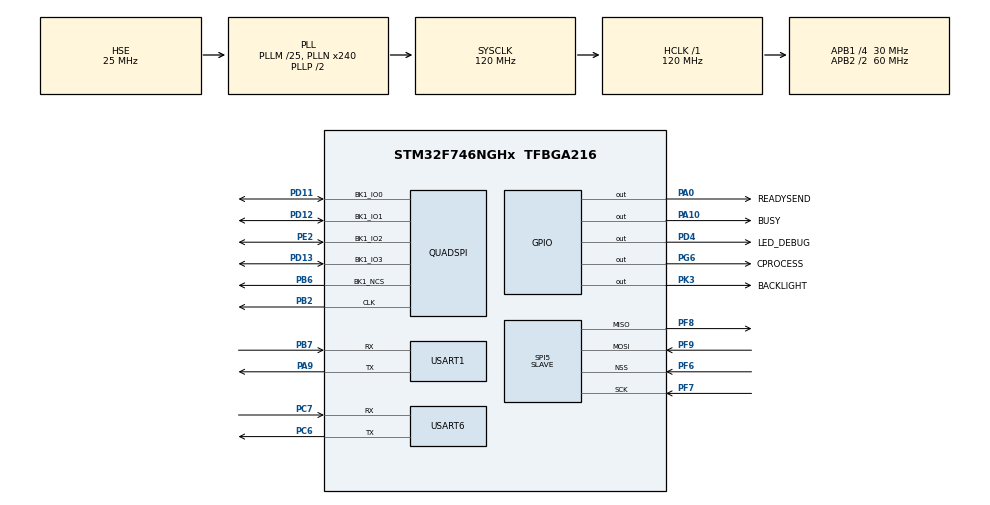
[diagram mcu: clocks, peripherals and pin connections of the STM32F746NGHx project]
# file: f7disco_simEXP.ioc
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CORTEX_M7.CPU_DCache=Disabled
CORTEX_M7.CPU_ICache=Disabled
CORTEX_M7.default_mode_Activation=0
Dma.Request0=SPI5_TX
Dma.SPI5_TX.0.Direction=DMA_MEMORY_TO_PERIPH
Dma.SPI5_TX.0.FIFOMode=DMA_FIFOMODE_DISABLE
Dma.SPI5_TX.0.Instance=DMA2_Stream4
Dma.SPI5_TX.0.MemDataAlignment=DMA_MDATAALIGN_BYTE
Dma.SPI5_TX.0.MemInc=DMA_MINC_ENABLE
Dma.SPI5_TX.0.Mode=DMA_NORMAL
Dma.SPI5_TX.0.PeriphDataAlignment=DMA_PDATAALIGN_BYTE
Dma.SPI5_TX.0.PeriphInc=DMA_PINC_DISABLE
Dma.SPI5_TX.0.Priority=DMA_PRIORITY_LOW
Mcu.Family=STM32F7
Mcu.Name=STM32F746NGHx
Mcu.Package=TFBGA216
NVIC.DMA2_Stream4_IRQn=true\:0\:0\:false\:false\:true\:false\:true\:true
NVIC.PriorityGroup=NVIC_PRIORITYGROUP_4
NVIC.SPI5_IRQn=true\:0\:0\:false\:false\:true\:true\:true\:true
NVIC.USART1_IRQn=true\:0\:0\:false\:false\:true\:true\:true\:true
NVIC.USART6_IRQn=true\:0\:0\:false\:false\:true\:true\:true\:true
PA0/WKUP.GPIO_Label=READYSEND
PA0/WKUP.PinState=GPIO_PIN_SET
PA0/WKUP.Signal=GPIO_Output
PA10.GPIO_Label=BUSY
PA10.PinState=GPIO_PIN_SET
PA10.Signal=GPIO_Output
PA9.Mode=Asynchronous
PA9.Signal=USART1_TX
PB2.Mode=Single Bank 1
PB2.Signal=QUADSPI_CLK
PB6.Mode=Single Bank 1
PB6.Signal=QUADSPI_BK1_NCS
PB7.Mode=Asynchronous
PB7.Signal=USART1_RX
PC6.Mode=Asynchronous
PC6.Signal=USART6_TX
PC7.Mode=Asynchronous
PC7.Signal=USART6_RX
PD11.Mode=Single Bank 1
PD11.Signal=QUADSPI_BK1_IO0
PD12.Mode=Single Bank 1
PD12.Signal=QUADSPI_BK1_IO1
PD13.Mode=Single Bank 1
PD13.Signal=QUADSPI_BK1_IO3
PD4.GPIO_Label=LED_DEBUG
PD4.Signal=GPIO_Output
PE2.Mode=Single Bank 1
PE2.Signal=QUADSPI_BK1_IO2
PF6.Mode=NSS_Signal_Hard_Input
PF6.Signal=SPI5_NSS
PF7.Mode=Full_Duplex_Slave
PF7.Signal=SPI5_SCK
PF8.Mode=Full_Duplex_Slave
PF8.Signal=SPI5_MISO
PF9.Mode=Full_Duplex_Slave
PF9.Signal=SPI5_MOSI
PG6.GPIO_Label=CPROCESS
PG6.PinState=GPIO_PIN_SET
PG6.Signal=GPIO_Output
PH0/OSC_IN.Mode=HSE-External-Clock-Source
PH0/OSC_IN.Signal=RCC_OSC_IN
PH1/OSC_OUT.Mode=HSE-External-Clock-Source
PH1/OSC_OUT.Signal=RCC_OSC_OUT
PK3.GPIO_Label=BACKLIGHT
PK3.Signal=GPIO_Output
ProjectManager.HeapSize=0x400
ProjectManager.StackSize=0x800
ProjectManager.TargetToolchain=STM32CubeIDE
QUADSPI.ChipSelectHighTime=QSPI_CS_HIGH_TIME_6_CYCLE
QUADSPI.ClockPrescaler=23
QUADSPI.FifoThreshold=4
QUADSPI.FlashSize=23
QUADSPI.SampleShifting=QSPI_SAMPLE_SHIFTING_HALFCYCLE
RCC.AHBFreq_Value=120000000
RCC.APB1CLKDivider=RCC_HCLK_DIV4
RCC.APB1Freq_Value=30000000
RCC.APB1TimFreq_Value=60000000
RCC.APB2CLKDivider=RCC_HCLK_DIV2
RCC.APB2Freq_Value=60000000
RCC.APB2TimFreq_Value=120000000
RCC.CortexFreq_Value=120000000
RCC.HCLKFreq_Value=120000000
RCC.HSE_VALUE=25000000
RCC.HSI_VALUE=16000000
RCC.LSE_VALUE=32768
RCC.PLLM=25
RCC.PLLN=240
RCC.PLLSourceVirtual=RCC_PLLSOURCE_HSE
RCC.SYSCLKFreq_VALUE=120000000
RCC.SYSCLKSource=RCC_SYSCLKSOURCE_PLLCLK
RCC.USBFreq_Value=120000000
RCC.VCOOutputFreq_Value=240000000
SPI5.DataSize=SPI_DATASIZE_8BIT
SPI5.Direction=SPI_DIRECTION_2LINES
SPI5.Mode=SPI_MODE_SLAVE
SPI5.VirtualNSS=VM_NSSHARD
SPI5.VirtualType=VM_SLAVE
USART1.VirtualMode-Asynchronous=VM_ASYNC
USART6.VirtualMode-Asynchronous=VM_ASYNC
board=custom

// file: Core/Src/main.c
/* USER CODE BEGIN Header */
/**
  ******************************************************************************
  * @file           : main.c
  * @brief          : Main program body
  ******************************************************************************
  * @attention
  *
  * Copyright (c) 2025 STMicroelectronics.
  * All rights reserved.
  *
  * This software is licensed under terms that can be found in the LICENSE file
  * in the root directory of this software component.
  * If no LICENSE file comes with this software, it is provided AS-IS.
  *
  ******************************************************************************
  */
/* USER CODE END Header */
#include "main.h"

/* USER CODE BEGIN Includes */
#include "stdio.h"
#include "Mgmt/mgmt.h"
#include "Logger/log.h"
/* USER CODE END Includes */

QSPI_HandleTypeDef hqspi;

UART_HandleTypeDef huart1;

void SystemClock_Config(void);
static void MX_GPIO_Init(void);
static void MX_DMA_Init(void);
static void MX_USART1_UART_Init(void);
static void MX_QUADSPI_Init(void);
static void MX_USART6_UART_Init(void);
static void MX_SPI5_Init(void);

/* USER CODE BEGIN 0 */
#define PRINTF2USART1 int __io_putchar(int data)
/* USER CODE END 0 */

int main(void)
{

  /* MCU Configuration--------------------------------------------------------*/

  /* Reset of all peripherals, Initializes the Flash interface and the Systick. */
  HAL_Init();

  /* Configure the system clock */
  SystemClock_Config();

  /* Initialize all configured peripherals */
  MX_GPIO_Init();
  MX_DMA_Init();
  MX_USART1_UART_Init();
  MX_QUADSPI_Init();
  MX_USART6_UART_Init();
  MX_SPI5_Init();
  /* USER CODE BEGIN 2 */
  Mgmt_SystemInitStepZero();

  Mgmt_SystemInitFinal();

  Mgmt_SystemStart();
  /* USER CODE END 2 */

  /* Infinite loop */
  while (1)
  {

  }
}

void SystemClock_Config(void)
{
  RCC_OscInitTypeDef RCC_OscInitStruct = {0};
  RCC_ClkInitTypeDef RCC_ClkInitStruct = {0};

  /** Configure the main internal regulator output voltage
  */
  __HAL_RCC_PWR_CLK_ENABLE();
  __HAL_PWR_VOLTAGESCALING_CONFIG(PWR_REGULATOR_VOLTAGE_SCALE3);

  /** Initializes the RCC Oscillators according to the specified parameters
  * in the RCC_OscInitTypeDef structure.
  */
  RCC_OscInitStruct.OscillatorType = RCC_OSCILLATORTYPE_HSE;
  RCC_OscInitStruct.HSEState = RCC_HSE_BYPASS;
  RCC_OscInitStruct.PLL.PLLState = RCC_PLL_ON;
  RCC_OscInitStruct.PLL.PLLSource = RCC_PLLSOURCE_HSE;
  RCC_OscInitStruct.PLL.PLLM = 25;
  RCC_OscInitStruct.PLL.PLLN = 240;
  RCC_OscInitStruct.PLL.PLLP = RCC_PLLP_DIV2;
  RCC_OscInitStruct.PLL.PLLQ = 2;
  if (HAL_RCC_OscConfig(&RCC_OscInitStruct) != HAL_OK)
  {
    Error_Handler();
  }

  /** Initializes the CPU, AHB and APB buses clocks
  */
  RCC_ClkInitStruct.ClockType = RCC_CLOCKTYPE_HCLK|RCC_CLOCKTYPE_SYSCLK
                              |RCC_CLOCKTYPE_PCLK1|RCC_CLOCKTYPE_PCLK2;
  RCC_ClkInitStruct.SYSCLKSource = RCC_SYSCLKSOURCE_PLLCLK;
  RCC_ClkInitStruct.AHBCLKDivider = RCC_SYSCLK_DIV1;
  RCC_ClkInitStruct.APB1CLKDivider = RCC_HCLK_DIV4;
  RCC_ClkInitStruct.APB2CLKDivider = RCC_HCLK_DIV2;

  if (HAL_RCC_ClockConfig(&RCC_ClkInitStruct, FLASH_LATENCY_3) != HAL_OK)
  {
    Error_Handler();
  }
}

static void MX_QUADSPI_Init(void)
{

  /* QUADSPI parameter configuration*/
  hqspi.Instance = QUADSPI;
  hqspi.Init.ClockPrescaler = 23;
  hqspi.Init.FifoThreshold = 4;
  hqspi.Init.SampleShifting = QSPI_SAMPLE_SHIFTING_HALFCYCLE;
  hqspi.Init.FlashSize = 23;
  hqspi.Init.ChipSelectHighTime = QSPI_CS_HIGH_TIME_6_CYCLE;
  hqspi.Init.ClockMode = QSPI_CLOCK_MODE_0;
  hqspi.Init.FlashID = QSPI_FLASH_ID_1;
  hqspi.Init.DualFlash = QSPI_DUALFLASH_DISABLE;
  if (HAL_QSPI_Init(&hqspi) != HAL_OK)
  {
    Error_Handler();
  }

}

static void MX_SPI5_Init(void)
{

  LL_SPI_InitTypeDef SPI_InitStruct = {0};

  LL_GPIO_InitTypeDef GPIO_InitStruct = {0};

  /* Peripheral clock enable */
  LL_APB2_GRP1_EnableClock(LL_APB2_GRP1_PERIPH_SPI5);

  LL_AHB1_GRP1_EnableClock(LL_AHB1_GRP1_PERIPH_GPIOF);
  /**SPI5 GPIO Configuration
  PF7   ------> SPI5_SCK
  PF6   ------> SPI5_NSS
  PF9   ------> SPI5_MOSI
  PF8   ------> SPI5_MISO
  */
  GPIO_InitStruct.Pin = LL_GPIO_PIN_7;
  GPIO_InitStruct.Mode = LL_GPIO_MODE_ALTERNATE;
  GPIO_InitStruct.Speed = LL_GPIO_SPEED_FREQ_VERY_HIGH;
  GPIO_InitStruct.OutputType = LL_GPIO_OUTPUT_PUSHPULL;
  GPIO_InitStruct.Pull = LL_GPIO_PULL_NO;
  GPIO_InitStruct.Alternate = LL_GPIO_AF_5;
  LL_GPIO_Init(GPIOF, &GPIO_InitStruct);

  GPIO_InitStruct.Pin = LL_GPIO_PIN_6;
  GPIO_InitStruct.Mode = LL_GPIO_MODE_ALTERNATE;
  GPIO_InitStruct.Speed = LL_GPIO_SPEED_FREQ_VERY_HIGH;
  GPIO_InitStruct.OutputType = LL_GPIO_OUTPUT_PUSHPULL;
  GPIO_InitStruct.Pull = LL_GPIO_PULL_NO;
  GPIO_InitStruct.Alternate = LL_GPIO_AF_5;
  LL_GPIO_Init(GPIOF, &GPIO_InitStruct);

  GPIO_InitStruct.Pin = LL_GPIO_PIN_9;
  GPIO_InitStruct.Mode = LL_GPIO_MODE_ALTERNATE;
  GPIO_InitStruct.Speed = LL_GPIO_SPEED_FREQ_VERY_HIGH;
  GPIO_InitStruct.OutputType = LL_GPIO_OUTPUT_PUSHPULL;
  GPIO_InitStruct.Pull = LL_GPIO_PULL_NO;
  GPIO_InitStruct.Alternate = LL_GPIO_AF_5;
  LL_GPIO_Init(GPIOF, &GPIO_InitStruct);

  GPIO_InitStruct.Pin = LL_GPIO_PIN_8;
  GPIO_InitStruct.Mode = LL_GPIO_MODE_ALTERNATE;
  GPIO_InitStruct.Speed = LL_GPIO_SPEED_FREQ_VERY_HIGH;
  GPIO_InitStruct.OutputType = LL_GPIO_OUTPUT_PUSHPULL;
  GPIO_InitStruct.Pull = LL_GPIO_PULL_NO;
  GPIO_InitStruct.Alternate = LL_GPIO_AF_5;
  LL_GPIO_Init(GPIOF, &GPIO_InitStruct);

  /* SPI5 DMA Init */

  /* SPI5_TX Init */
  LL_DMA_SetChannelSelection(DMA2, LL_DMA_STREAM_4, LL_DMA_CHANNEL_2);

  LL_DMA_SetDataTransferDirection(DMA2, LL_DMA_STREAM_4, LL_DMA_DIRECTION_MEMORY_TO_PERIPH);

  LL_DMA_SetStreamPriorityLevel(DMA2, LL_DMA_STREAM_4, LL_DMA_PRIORITY_LOW);

  LL_DMA_SetMode(DMA2, LL_DMA_STREAM_4, LL_DMA_MODE_NORMAL);

  LL_DMA_SetPeriphIncMode(DMA2, LL_DMA_STREAM_4, LL_DMA_PERIPH_NOINCREMENT);

  LL_DMA_SetMemoryIncMode(DMA2, LL_DMA_STREAM_4, LL_DMA_MEMORY_INCREMENT);

  LL_DMA_SetPeriphSize(DMA2, LL_DMA_STREAM_4, LL_DMA_PDATAALIGN_BYTE);

  LL_DMA_SetMemorySize(DMA2, LL_DMA_STREAM_4, LL_DMA_MDATAALIGN_BYTE);

  LL_DMA_DisableFifoMode(DMA2, LL_DMA_STREAM_4);

  /* SPI5 interrupt Init */
  NVIC_SetPriority(SPI5_IRQn, NVIC_EncodePriority(NVIC_GetPriorityGrouping(),0, 0));
  NVIC_EnableIRQ(SPI5_IRQn);

  /* SPI5 parameter configuration*/
  SPI_InitStruct.TransferDirection = LL_SPI_FULL_DUPLEX;
  SPI_InitStruct.Mode = LL_SPI_MODE_SLAVE;
  SPI_InitStruct.DataWidth = LL_SPI_DATAWIDTH_8BIT;
  SPI_InitStruct.ClockPolarity = LL_SPI_POLARITY_LOW;
  SPI_InitStruct.ClockPhase = LL_SPI_PHASE_1EDGE;
  SPI_InitStruct.NSS = LL_SPI_NSS_HARD_INPUT;
  SPI_InitStruct.BitOrder = LL_SPI_MSB_FIRST;
  SPI_InitStruct.CRCCalculation = LL_SPI_CRCCALCULATION_DISABLE;
  SPI_InitStruct.CRCPoly = 7;
  LL_SPI_Init(SPI5, &SPI_InitStruct);
  LL_SPI_SetStandard(SPI5, LL_SPI_PROTOCOL_MOTOROLA);
  LL_SPI_DisableNSSPulseMgt(SPI5);

}

static void MX_USART1_UART_Init(void)
{

  huart1.Instance = USART1;
  huart1.Init.BaudRate = 115200;
  huart1.Init.WordLength = UART_WORDLENGTH_8B;
  huart1.Init.StopBits = UART_STOPBITS_1;
  huart1.Init.Parity = UART_PARITY_NONE;
  huart1.Init.Mode = UART_MODE_TX_RX;
  huart1.Init.HwFlowCtl = UART_HWCONTROL_NONE;
  huart1.Init.OverSampling = UART_OVERSAMPLING_16;
  huart1.Init.OneBitSampling = UART_ONE_BIT_SAMPLE_DISABLE;
  huart1.AdvancedInit.AdvFeatureInit = UART_ADVFEATURE_NO_INIT;
  if (HAL_UART_Init(&huart1) != HAL_OK)
  {
    Error_Handler();
  }

}

static void MX_USART6_UART_Init(void)
{

  LL_USART_InitTypeDef USART_InitStruct = {0};

  LL_GPIO_InitTypeDef GPIO_InitStruct = {0};
  RCC_PeriphCLKInitTypeDef PeriphClkInitStruct = {0};

  /** Initializes the peripherals clock
  */
  PeriphClkInitStruct.PeriphClockSelection = RCC_PERIPHCLK_USART6;
  PeriphClkInitStruct.Usart6ClockSelection = RCC_USART6CLKSOURCE_PCLK2;
  if (HAL_RCCEx_PeriphCLKConfig(&PeriphClkInitStruct) != HAL_OK)
  {
    Error_Handler();
  }

  /* Peripheral clock enable */
  LL_APB2_GRP1_EnableClock(LL_APB2_GRP1_PERIPH_USART6);

  LL_AHB1_GRP1_EnableClock(LL_AHB1_GRP1_PERIPH_GPIOC);
  /**USART6 GPIO Configuration
  PC7   ------> USART6_RX
  PC6   ------> USART6_TX
  */
  GPIO_InitStruct.Pin = LL_GPIO_PIN_7;
  GPIO_InitStruct.Mode = LL_GPIO_MODE_ALTERNATE;
  GPIO_InitStruct.Speed = LL_GPIO_SPEED_FREQ_VERY_HIGH;
  GPIO_InitStruct.OutputType = LL_GPIO_OUTPUT_PUSHPULL;
  GPIO_InitStruct.Pull = LL_GPIO_PULL_NO;
  GPIO_InitStruct.Alternate = LL_GPIO_AF_8;
  LL_GPIO_Init(GPIOC, &GPIO_InitStruct);

  GPIO_InitStruct.Pin = LL_GPIO_PIN_6;
  GPIO_InitStruct.Mode = LL_GPIO_MODE_ALTERNATE;
  GPIO_InitStruct.Speed = LL_GPIO_SPEED_FREQ_VERY_HIGH;
  GPIO_InitStruct.OutputType = LL_GPIO_OUTPUT_PUSHPULL;
  GPIO_InitStruct.Pull = LL_GPIO_PULL_NO;
  GPIO_InitStruct.Alternate = LL_GPIO_AF_8;
  LL_GPIO_Init(GPIOC, &GPIO_InitStruct);

  /* USART6 interrupt Init */
  NVIC_SetPriority(USART6_IRQn, NVIC_EncodePriority(NVIC_GetPriorityGrouping(),0, 0));
  NVIC_EnableIRQ(USART6_IRQn);

  USART_InitStruct.BaudRate = 115200;
  USART_InitStruct.DataWidth = LL_USART_DATAWIDTH_8B;
  USART_InitStruct.StopBits = LL_USART_STOPBITS_1;
  USART_InitStruct.Parity = LL_USART_PARITY_NONE;
  USART_InitStruct.TransferDirection = LL_USART_DIRECTION_TX_RX;
  USART_InitStruct.HardwareFlowControl = LL_USART_HWCONTROL_NONE;
  USART_InitStruct.OverSampling = LL_USART_OVERSAMPLING_16;
  LL_USART_Init(USART6, &USART_InitStruct);
  LL_USART_ConfigAsyncMode(USART6);
  LL_USART_Enable(USART6);

}

static void MX_DMA_Init(void)
{

  /* Init with LL driver */
  /* DMA controller clock enable */
  LL_AHB1_GRP1_EnableClock(LL_AHB1_GRP1_PERIPH_DMA2);

  /* DMA interrupt init */
  /* DMA2_Stream4_IRQn interrupt configuration */
  NVIC_SetPriority(DMA2_Stream4_IRQn, NVIC_EncodePriority(NVIC_GetPriorityGrouping(),0, 0));
  NVIC_EnableIRQ(DMA2_Stream4_IRQn);

}

static void MX_GPIO_Init(void)
{
  LL_GPIO_InitTypeDef GPIO_InitStruct = {0};

  /* GPIO Ports Clock Enable */
  LL_AHB1_GRP1_EnableClock(LL_AHB1_GRP1_PERIPH_GPIOE);
  LL_AHB1_GRP1_EnableClock(LL_AHB1_GRP1_PERIPH_GPIOB);
  LL_AHB1_GRP1_EnableClock(LL_AHB1_GRP1_PERIPH_GPIOK);
  LL_AHB1_GRP1_EnableClock(LL_AHB1_GRP1_PERIPH_GPIOD);
  LL_AHB1_GRP1_EnableClock(LL_AHB1_GRP1_PERIPH_GPIOA);
  LL_AHB1_GRP1_EnableClock(LL_AHB1_GRP1_PERIPH_GPIOH);
  LL_AHB1_GRP1_EnableClock(LL_AHB1_GRP1_PERIPH_GPIOC);
  LL_AHB1_GRP1_EnableClock(LL_AHB1_GRP1_PERIPH_GPIOG);
  LL_AHB1_GRP1_EnableClock(LL_AHB1_GRP1_PERIPH_GPIOF);

  /**/
  LL_GPIO_ResetOutputPin(BACKLIGHT_GPIO_Port, BACKLIGHT_Pin);

  /**/
  LL_GPIO_ResetOutputPin(LED_DEBUG_GPIO_Port, LED_DEBUG_Pin);

  /**/
  LL_GPIO_SetOutputPin(BUSY_GPIO_Port, BUSY_Pin);

  /**/
  LL_GPIO_SetOutputPin(CPROCESS_GPIO_Port, CPROCESS_Pin);

  /**/
  LL_GPIO_SetOutputPin(READYSEND_GPIO_Port, READYSEND_Pin);

  /**/
  GPIO_InitStruct.Pin = BACKLIGHT_Pin;
  GPIO_InitStruct.Mode = LL_GPIO_MODE_OUTPUT;
  GPIO_InitStruct.Speed = LL_GPIO_SPEED_FREQ_LOW;
  GPIO_InitStruct.OutputType = LL_GPIO_OUTPUT_PUSHPULL;
  GPIO_InitStruct.Pull = LL_GPIO_PULL_NO;
  LL_GPIO_Init(BACKLIGHT_GPIO_Port, &GPIO_InitStruct);

  /**/
  GPIO_InitStruct.Pin = LED_DEBUG_Pin;
  GPIO_InitStruct.Mode = LL_GPIO_MODE_OUTPUT;
  GPIO_InitStruct.Speed = LL_GPIO_SPEED_FREQ_LOW;
  GPIO_InitStruct.OutputType = LL_GPIO_OUTPUT_PUSHPULL;
  GPIO_InitStruct.Pull = LL_GPIO_PULL_NO;
  LL_GPIO_Init(LED_DEBUG_GPIO_Port, &GPIO_InitStruct);

  /**/
  GPIO_InitStruct.Pin = BUSY_Pin;
  GPIO_InitStruct.Mode = LL_GPIO_MODE_OUTPUT;
  GPIO_InitStruct.Speed = LL_GPIO_SPEED_FREQ_LOW;
  GPIO_InitStruct.OutputType = LL_GPIO_OUTPUT_PUSHPULL;
  GPIO_InitStruct.Pull = LL_GPIO_PULL_NO;
  LL_GPIO_Init(BUSY_GPIO_Port, &GPIO_InitStruct);

  /**/
  GPIO_InitStruct.Pin = CPROCESS_Pin;
  GPIO_InitStruct.Mode = LL_GPIO_MODE_OUTPUT;
  GPIO_InitStruct.Speed = LL_GPIO_SPEED_FREQ_LOW;
  GPIO_InitStruct.OutputType = LL_GPIO_OUTPUT_PUSHPULL;
  GPIO_InitStruct.Pull = LL_GPIO_PULL_NO;
  LL_GPIO_Init(CPROCESS_GPIO_Port, &GPIO_InitStruct);

  /**/
  GPIO_InitStruct.Pin = READYSEND_Pin;
  GPIO_InitStruct.Mode = LL_GPIO_MODE_OUTPUT;
  GPIO_InitStruct.Speed = LL_GPIO_SPEED_FREQ_LOW;
  GPIO_InitStruct.OutputType = LL_GPIO_OUTPUT_PUSHPULL;
  GPIO_InitStruct.Pull = LL_GPIO_PULL_NO;
  LL_GPIO_Init(READYSEND_GPIO_Port, &GPIO_InitStruct);

}

/* USER CODE BEGIN 4 */
PRINTF2USART1{
	HAL_UART_Transmit(&huart1, (uint8_t *) &data, 1, 0xFFFF);
	return data;
}
/* USER CODE END 4 */

void Error_Handler(void)
{
  /* USER CODE BEGIN Error_Handler_Debug */
  /* User can add his own implementation to report the HAL error return state */
  while (1)
  {
		LL_GPIO_ResetOutputPin(LED_DEBUG_GPIO_Port, LED_DEBUG_Pin);
		HAL_Delay(50);
		LL_GPIO_SetOutputPin(LED_DEBUG_GPIO_Port, LED_DEBUG_Pin);
		HAL_Delay(50);
  }
  __disable_irq();
  while (1)
  {
  }
  /* USER CODE END Error_Handler_Debug */
}
